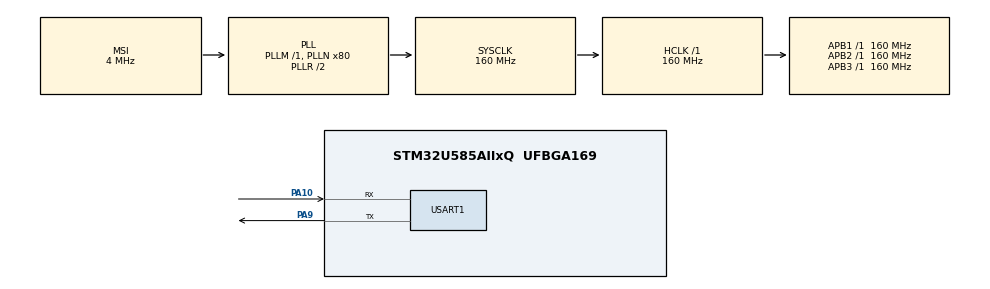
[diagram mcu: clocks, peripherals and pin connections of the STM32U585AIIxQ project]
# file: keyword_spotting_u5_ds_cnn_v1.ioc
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CORTEX_M33_NS.userName=CORTEX_M33
Mcu.Family=STM32U5
Mcu.Name=STM32U585AIIxQ
Mcu.Package=UFBGA169
NVIC.PriorityGroup=NVIC_PRIORITYGROUP_4
PA10.Mode=Asynchronous
PA10.Signal=USART1_RX
PA9.Mode=Asynchronous
PA9.Signal=USART1_TX
ProjectManager.HeapSize=0x2000
ProjectManager.StackSize=0x4000
ProjectManager.TargetToolchain=STM32CubeIDE
RCC.ADCFreq_Value=16000000
RCC.AHBFreq_Value=160000000
RCC.APB1Freq_Value=160000000
RCC.APB1TimFreq_Value=160000000
RCC.APB2Freq_Value=160000000
RCC.APB2TimFreq_Value=160000000
RCC.APB3Freq_Value=160000000
RCC.CortexFreq_Value=160000000
RCC.DACCLockSelectionVirtual=RCC_DAC1CLKSOURCE_LSI
RCC.EPOD_VALUE=4000000
RCC.HCLKFreq_Value=160000000
RCC.HSE_VALUE=16000000
RCC.HSI48_VALUE=48000000
RCC.HSI_VALUE=16000000
RCC.LSE_VALUE=32768
RCC.LSIDIV_VALUE=32000
RCC.MSI_VALUE=4000000
RCC.PLLN=80
RCC.SYSCLKFreq_VALUE=160000000
RCC.SYSCLKSource=RCC_SYSCLKSOURCE_PLLCLK
RCC.USBFreq_Value=48000000
RCC.VCOOutputFreq_Value=320000000
STMicroelectronics.X-CUBE-AI.10.2.0.ActivationBufferSizeList=26792
STMicroelectronics.X-CUBE-AI.10.2.0.ActivationBuffers=pool0
STMicroelectronics.X-CUBE-AI.10.2.0.ActivationNames=pool0
STMicroelectronics.X-CUBE-AI.10.2.0.ActivationSizes=AI_NETWORK_DATA_ACTIVATION_1_SIZE
STMicroelectronics.X-CUBE-AI.10.2.0.ApplicationCcDeviceJjApplication=Validation
STMicroelectronics.X-CUBE-AI.10.2.0.BSP.number=1
STMicroelectronics.X-CUBE-AI.10.2.0.HeapSize=0x2000
STMicroelectronics.X-CUBE-AI.10.2.0.InternalRamActivationBufferMaxSize=AI_NETWORK_DATA_ACTIVATIONS_SIZE
STMicroelectronics.X-CUBE-AI.10.2.0.LatestDirectoryUsed-bee9b38473e57b4d3415938a8f338734ecbbc4747ba164b42dfc6d9c1230494e=/home/pascal/Documents/ml_on_mcu/MLonMCU_Project/cnn-trad-fpool3_model/models
STMicroelectronics.X-CUBE-AI.10.2.0.MaximumNumberOfInputLayer=1
STMicroelectronics.X-CUBE-AI.10.2.0.MaximumNumberOfOutputLayer=1
STMicroelectronics.X-CUBE-AI.10.2.0.MaximumSizeOfInputLayer=1
STMicroelectronics.X-CUBE-AI.10.2.0.MaximumSizeOfOutputLayer=1
STMicroelectronics.X-CUBE-AI.10.2.0.ModelActualCompression-bee9b38473e57b4d3415938a8f338734ecbbc4747ba164b42dfc6d9c1230494e=0.0
STMicroelectronics.X-CUBE-AI.10.2.0.ModelCompression-bee9b38473e57b4d3415938a8f338734ecbbc4747ba164b42dfc6d9c1230494e=None
STMicroelectronics.X-CUBE-AI.10.2.0.ModelFlashOccupation-bee9b38473e57b4d3415938a8f338734ecbbc4747ba164b42dfc6d9c1230494e=78485
STMicroelectronics.X-CUBE-AI.10.2.0.ModelHashList=bee9b38473e57b4d3415938a8f338734ecbbc4747ba164b42dfc6d9c1230494e
STMicroelectronics.X-CUBE-AI.10.2.0.ModelKind-bee9b38473e57b4d3415938a8f338734ecbbc4747ba164b42dfc6d9c1230494e=TFLITE
STMicroelectronics.X-CUBE-AI.10.2.0.ModelMacc-bee9b38473e57b4d3415938a8f338734ecbbc4747ba164b42dfc6d9c1230494e=3833472
STMicroelectronics.X-CUBE-AI.10.2.0.ModelName-bee9b38473e57b4d3415938a8f338734ecbbc4747ba164b42dfc6d9c1230494e=network
STMicroelectronics.X-CUBE-AI.10.2.0.ModelNameList=network
STMicroelectronics.X-CUBE-AI.10.2.0.ModelRamOccupation-bee9b38473e57b4d3415938a8f338734ecbbc4747ba164b42dfc6d9c1230494e=26792
STMicroelectronics.X-CUBE-AI.10.2.0.ModelStructureFile-bee9b38473e57b4d3415938a8f338734ecbbc4747ba164b42dfc6d9c1230494e=/home/pascal/Documents/ml_on_mcu/MLonMCU_Project/cnn-trad-fpool3_model/models/ds_cnn_l.tflite
STMicroelectronics.X-CUBE-AI.10.2.0.ModelType-bee9b38473e57b4d3415938a8f338734ecbbc4747ba164b42dfc6d9c1230494e=STM32Cube.AI MCU runtime
STMicroelectronics.X-CUBE-AI.10.2.0.ReadyForCodeGeneration=true
STMicroelectronics.X-CUBE-AI.10.2.0.StackSize=0x4000
STMicroelectronics.X-CUBE-AI.10.2.0.WorkingBufferStartAddrList=0xFFFFFFFF
STMicroelectronics.X-CUBE-AI.10.2.0.XAaCUBEAaAICcArtificialOoIntelligenceJjCore=true
STMicroelectronics.X-CUBE-AI.10.2.0.copyWeightToRam=false
STMicroelectronics.X-CUBE-AI.10.2.0.customLayerConfigEnabled=false
STMicroelectronics.X-CUBE-AI.10.2.0.noOnnxIoTranspose=false
STMicroelectronics.X-CUBE-AI.10.2.0.useInputAllocation=true
STMicroelectronics.X-CUBE-AI.10.2.0.useOutputAllocation=true
STMicroelectronics.X-CUBE-AI.10.2.00.BSP.STBoard=false
STMicroelectronics.X-CUBE-AI.10.2.00.BSP.api=Unknown
STMicroelectronics.X-CUBE-AI.10.2.00.BSP.condition=\!SEMDeviceJjApplicationJjApplicationTemplate
STMicroelectronics.X-CUBE-AI.10.2.00.BSP.instance=USART1
STMicroelectronics.X-CUBE-AI.10.2.00.BSP.ip=USART
STMicroelectronics.X-CUBE-AI.10.2.00.BSP.mode=Asynchronous
STMicroelectronics.X-CUBE-AI.10.2.00.BSP.name=COM Port
STMicroelectronics.X-CUBE-AI.10.2.00.BSP.solution=USART1
USART1.VirtualMode-Asynchronous=VM_ASYNC
VP_ICACHE_VS_ICACHE.Mode=DefaultMode
VP_LPBAMQUEUE_VS_QUEUE.Mode=QUEUEMODE
VP_LPBAM_VS_SIG1.Mode=SmartRun
VP_LPBAM_VS_SIG4.Mode=LPDMA1
VP_MEMORYMAP_VS_MEMORYMAP.Mode=CurAppReg
VP_PWR_VS_SECSignals.Mode=Security/Privilege
VP_STMicroelectronics.X-CUBE-AI_VS_ArtificialOoIntelligenceJjXAaCUBEAaAI_10.2.0.Mode=ArtificialOoIntelligenceJjXAaCUBEAaAI
VP_STMicroelectronics.X-CUBE-AI_VS_DeviceJjApplication_10.2.0.Mode=DeviceJjApplication
board=B-U585I-IOT02A

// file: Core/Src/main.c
/* USER CODE BEGIN Header */
/**
  ******************************************************************************
  * @file           : main.c
  * @brief          : Main program body
  ******************************************************************************
  * @attention
  *
  * Copyright (c) 2026 STMicroelectronics.
  * All rights reserved.
  *
  * This software is licensed under terms that can be found in the LICENSE file
  * in the root directory of this software component.
  * If no LICENSE file comes with this software, it is provided AS-IS.
  *
  ******************************************************************************
  */
/* USER CODE END Header */
#include "main.h"
#include "app_x-cube-ai.h"

/* USER CODE BEGIN Includes */
#include "mic_debug.h"
#include "kws20_mode_config.h"
#include "kws20_measure.h"
#include "kws20_test.h"
#include "kws20_live.h"
#include <stdio.h>

/* USER CODE END Includes */

UART_HandleTypeDef huart1;

void SystemClock_Config(void);
static void MX_GPIO_Init(void);
static void MX_ICACHE_Init(void);
/* USER CODE BEGIN PFP */
void mic2_poll_run_forever(void);
void mic2_input_test_run_once(void);
void audio_hw_probe_run_once(void);
void audio_st_minimal_run_once(void);

/* USER CODE END PFP */

int main(void)
{

  /* MCU Configuration--------------------------------------------------------*/

  /* Reset of all peripherals, Initializes the Flash interface and the Systick. */
  HAL_Init();

  /* Configure the system clock */
  SystemClock_Config();

  /* Initialize all configured peripherals */

  MX_GPIO_Init();
  MX_ICACHE_Init();
  MX_USART1_UART_Init();
  MX_X_CUBE_AI_Init();
  /* USER CODE BEGIN 2 */
#if KWS20_CFG_APP_MODE == KWS20_CFG_APP_MODE_MIC2_POLL
  mic2_poll_run_forever();
#elif KWS20_CFG_APP_MODE == KWS20_CFG_APP_MODE_AUDIO_HW_PROBE
  audio_hw_probe_run_once();
#elif KWS20_CFG_APP_MODE == KWS20_CFG_APP_MODE_AUDIO_MINIMAL
  audio_st_minimal_run_once();
#elif KWS20_CFG_ENABLE_MEASURE
#if KWS20_CFG_MEASURE_LIVE
  kws20_live_run_once();
#else
  kws20_measure_run_once();
#endif
#else
  kws20_live_run_once();
#endif
  /* USER CODE END 2 */

  /* Infinite loop */
  while (1)
  {

  /* MX_X_CUBE_AI_Process(); */
  }
}

void SystemClock_Config(void)
{
  RCC_OscInitTypeDef RCC_OscInitStruct = {0};
  RCC_ClkInitTypeDef RCC_ClkInitStruct = {0};

  /** Configure the main internal regulator output voltage
  */
  if (HAL_PWREx_ControlVoltageScaling(PWR_REGULATOR_VOLTAGE_SCALE1) != HAL_OK)
  {
    Error_Handler();
  }

  /** Initializes the CPU, AHB and APB buses clocks
  */
  RCC_OscInitStruct.OscillatorType = RCC_OSCILLATORTYPE_MSI;
  RCC_OscInitStruct.MSIState = RCC_MSI_ON;
  RCC_OscInitStruct.MSICalibrationValue = RCC_MSICALIBRATION_DEFAULT;
  RCC_OscInitStruct.MSIClockRange = RCC_MSIRANGE_4;
  RCC_OscInitStruct.PLL.PLLState = RCC_PLL_ON;
  RCC_OscInitStruct.PLL.PLLSource = RCC_PLLSOURCE_MSI;
  RCC_OscInitStruct.PLL.PLLMBOOST = RCC_PLLMBOOST_DIV1;
  RCC_OscInitStruct.PLL.PLLM = 1;
  RCC_OscInitStruct.PLL.PLLN = 80;
  RCC_OscInitStruct.PLL.PLLP = 2;
  RCC_OscInitStruct.PLL.PLLQ = 2;
  RCC_OscInitStruct.PLL.PLLR = 2;
  RCC_OscInitStruct.PLL.PLLRGE = RCC_PLLVCIRANGE_0;
  RCC_OscInitStruct.PLL.PLLFRACN = 0;
  if (HAL_RCC_OscConfig(&RCC_OscInitStruct) != HAL_OK)
  {
    Error_Handler();
  }

  /** Initializes the CPU, AHB and APB buses clocks
  */
  RCC_ClkInitStruct.ClockType = RCC_CLOCKTYPE_HCLK|RCC_CLOCKTYPE_SYSCLK
                              |RCC_CLOCKTYPE_PCLK1|RCC_CLOCKTYPE_PCLK2
                              |RCC_CLOCKTYPE_PCLK3;
  RCC_ClkInitStruct.SYSCLKSource = RCC_SYSCLKSOURCE_PLLCLK;
  RCC_ClkInitStruct.AHBCLKDivider = RCC_SYSCLK_DIV1;
  RCC_ClkInitStruct.APB1CLKDivider = RCC_HCLK_DIV1;
  RCC_ClkInitStruct.APB2CLKDivider = RCC_HCLK_DIV1;
  RCC_ClkInitStruct.APB3CLKDivider = RCC_HCLK_DIV1;

  if (HAL_RCC_ClockConfig(&RCC_ClkInitStruct, FLASH_LATENCY_4) != HAL_OK)
  {
    Error_Handler();
  }
}

static void MX_ICACHE_Init(void)
{

  /** Enable instruction cache (default 2-ways set associative cache)
  */
  if (HAL_ICACHE_Enable() != HAL_OK)
  {
    Error_Handler();
  }

}

void MX_USART1_UART_Init(void)
{

  huart1.Instance = USART1;
  huart1.Init.BaudRate = 115200;
  huart1.Init.WordLength = UART_WORDLENGTH_8B;
  huart1.Init.StopBits = UART_STOPBITS_1;
  huart1.Init.Parity = UART_PARITY_NONE;
  huart1.Init.Mode = UART_MODE_TX_RX;
  huart1.Init.HwFlowCtl = UART_HWCONTROL_NONE;
  huart1.Init.OverSampling = UART_OVERSAMPLING_16;
  huart1.Init.OneBitSampling = UART_ONE_BIT_SAMPLE_DISABLE;
  huart1.Init.ClockPrescaler = UART_PRESCALER_DIV1;
  huart1.AdvancedInit.AdvFeatureInit = UART_ADVFEATURE_NO_INIT;
  if (HAL_UART_Init(&huart1) != HAL_OK)
  {
    Error_Handler();
  }
  if (HAL_UARTEx_SetTxFifoThreshold(&huart1, UART_TXFIFO_THRESHOLD_1_8) != HAL_OK)
  {
    Error_Handler();
  }
  if (HAL_UARTEx_SetRxFifoThreshold(&huart1, UART_RXFIFO_THRESHOLD_1_8) != HAL_OK)
  {
    Error_Handler();
  }
  if (HAL_UARTEx_DisableFifoMode(&huart1) != HAL_OK)
  {
    Error_Handler();
  }

}

static void MX_GPIO_Init(void)
{

  /* GPIO Ports Clock Enable */
  __HAL_RCC_GPIOA_CLK_ENABLE();

}

/* USER CODE BEGIN 4 */
int __io_putchar(int ch)
{
  HAL_UART_Transmit(&huart1, (uint8_t *)&ch, 1, HAL_MAX_DELAY);
  return ch;
}
/* USER CODE END 4 */

void Error_Handler(void)
{
  __disable_irq();
  while (1)
  {
  }
}
